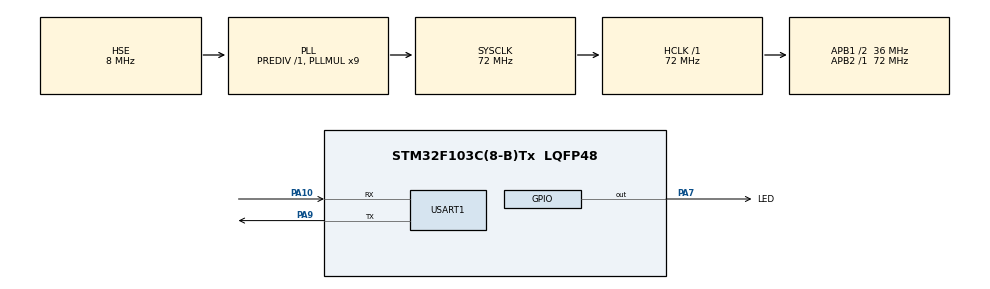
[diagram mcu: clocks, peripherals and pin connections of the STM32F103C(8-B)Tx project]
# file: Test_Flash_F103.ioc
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Mcu.Family=STM32F1
Mcu.Name=STM32F103C(8-B)Tx
Mcu.Package=LQFP48
NVIC.PriorityGroup=NVIC_PRIORITYGROUP_4
PA10.Mode=Asynchronous
PA10.Signal=USART1_RX
PA13.Mode=Serial_Wire
PA13.Signal=SYS_JTMS-SWDIO
PA14.Mode=Serial_Wire
PA14.Signal=SYS_JTCK-SWCLK
PA7.GPIO_Label=LED
PA7.Signal=GPIO_Output
PA9.Mode=Asynchronous
PA9.Signal=USART1_TX
PD0-OSC_IN.Mode=HSE-External-Oscillator
PD0-OSC_IN.Signal=RCC_OSC_IN
PD1-OSC_OUT.Mode=HSE-External-Oscillator
PD1-OSC_OUT.Signal=RCC_OSC_OUT
ProjectManager.HeapSize=0x200
ProjectManager.StackSize=0x400
ProjectManager.TargetToolchain=TrueSTUDIO
RCC.AHBFreq_Value=72000000
RCC.APB1CLKDivider=RCC_HCLK_DIV2
RCC.APB1Freq_Value=36000000
RCC.APB1TimFreq_Value=72000000
RCC.APB2Freq_Value=72000000
RCC.APB2TimFreq_Value=72000000
RCC.HCLKFreq_Value=72000000
RCC.PLLMUL=RCC_PLL_MUL9
RCC.PLLSourceVirtual=RCC_PLLSOURCE_HSE
RCC.SYSCLKFreq_VALUE=72000000
RCC.SYSCLKSource=RCC_SYSCLKSOURCE_PLLCLK
RCC.USBFreq_Value=72000000
USART1.VirtualMode=VM_ASYNC
board=custom

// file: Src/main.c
/* USER CODE BEGIN Header */
/**
  ******************************************************************************
  * @file           : main.c
  * @brief          : Main program body
  ******************************************************************************
  * @attention
  *
  * <h2><center>&copy; Copyright (c) 2019 STMicroelectronics.
  * All rights reserved.</center></h2>
  *
  * This software component is licensed by ST under BSD 3-Clause license,
  * the "License"; You may not use this file except in compliance with the
  * License. You may obtain a copy of the License at:
  *                        opensource.org/licenses/BSD-3-Clause
  *
  ******************************************************************************
  */
/* USER CODE END Header */

#include "main.h"

/* USER CODE BEGIN Includes */
#include "string.h"
#include "stdio.h"
#include "addr_pages.h"
/* USER CODE END Includes */

UART_HandleTypeDef huart1;

void SystemClock_Config(void);
static void MX_GPIO_Init(void);
static void MX_USART1_UART_Init(void);

/* USER CODE BEGIN 0 */
/*#define ENDMEMORY (0x0801FC00 + 1024) // последняя ячейка флеша (F103)

uint32_t flash_search_adress(uint32_t address, uint8_t cnt)
{
	uint8_t count_byte = cnt;

	while(count_byte)
	{
		if(0xFF == *(uint8_t*)address++) count_byte--;
		else count_byte = cnt;

		if(address == ENDMEMORY - 1) return 0;
	}

	return address -= cnt;
}*/
/* USER CODE END 0 */

int main(void)
{

  /* MCU Configuration--------------------------------------------------------*/

  /* Reset of all peripherals, Initializes the Flash interface and the Systick. */
  HAL_Init();

  /* Configure the system clock */
  SystemClock_Config();

  /* Initialize all configured peripherals */
  MX_GPIO_Init();
  MX_USART1_UART_Init();
  /* USER CODE BEGIN 2 */

  HAL_UART_Transmit(&huart1, (uint8_t*)"Start\n", 6, 100);
  //////////////////////////////////////////////////////////////////////////////////////////////////////////////////
  /////////////////////////////////////////// РАБОТА с ФЛЕШЕМ //////////////////////////////////////////////////////
  //////////////////////////////////////////////////////////////////////////////////////////////////////////////////

  #define MYADDR ADDR_FLASH_PAGE_127

  static FLASH_EraseInitTypeDef EraseInitStruct; // структура для очистки флеша

  EraseInitStruct.TypeErase = FLASH_TYPEERASE_PAGES; // постраничная очистка, FLASH_TYPEERASE_MASSERASE - очистка всего флеша
  EraseInitStruct.PageAddress = MYADDR; // адрес 127-ой страницы
  EraseInitStruct.NbPages = 1;                       // кол-во страниц для стирания
  //EraseInitStruct.Banks = FLASH_BANK_1; // FLASH_BANK_2 - банк №2, FLASH_BANK_BOTH - оба банка

  uint32_t page_error = 0; // переменная, в которую запишется адрес страницы при неудачном стирании

  char str[64] = {0,};

  ////////////////////////////// ОЧИСТКА ///////////////////////////////////
  HAL_FLASH_Unlock(); // разблокировать флеш

  if(HAL_FLASHEx_Erase(&EraseInitStruct, &page_error) != HAL_OK)
  {
	  uint32_t er = HAL_FLASH_GetError();
	  snprintf(str, 64, "ER %lu\n", er);
	  HAL_UART_Transmit(&huart1, (uint8_t*)str, strlen(str), 100);
	  while(1){}
  }

  HAL_UART_Transmit(&huart1, (uint8_t*)"Erase OK\n", 9, 100);

  HAL_FLASH_Lock(); // заблокировать флеш
  ///////////////////////// КОНЕЦ ОЧИСТКИ //////////////////////////////

  // 0x00U - No error
  // 0x01U - Programming error
  // 0x02U - Write protection error
  // 0x04U - Option validity error

  ////////////////////////////// ЗАПИСЬ числа 16 bits ///////////////////////////////////
  HAL_FLASH_Unlock(); // разблокировать флеш

  uint32_t address = MYADDR; // запись в начало страницы 127
  uint16_t idata[] = {0x1941, 0x1945};    // массив из двух чисел для записи

  for(uint8_t i = 0; i < 2; i++)
  {
	  if(HAL_FLASH_Program(FLASH_TYPEPROGRAM_HALFWORD, address, idata[i]) != HAL_OK)
	  {
		  uint32_t er = HAL_FLASH_GetError();
		  snprintf(str, 64, "ER %lu\n", er);
		  HAL_UART_Transmit(&huart1, (uint8_t*)str, strlen(str), 100);
		  while(1){}
	  }

	  address = address + 2;
  }

  HAL_UART_Transmit(&huart1, (uint8_t*)"Write 16 bits OK\n", strlen("Write 16 bits OK\n"), 100);

  HAL_FLASH_Lock(); // заблокировать флеш
  /////////////////////// КОНЕЦ ЗАПИСИ числа 16 bits ///////////////////////////

  ////////////////////////////// ЧТЕНИЕ числа 16 bits ///////////////////////////////////
  address = MYADDR;

  for(uint16_t i = 0; i < 2; i++)
  {
	  uint16_t dig16 = *(uint16_t*)address; // читаем число по адресу

	  snprintf(str, 64, "READ_%d Dec: %d Hex: 0x%04X\n", i, dig16, dig16);
	  HAL_UART_Transmit(&huart1, (uint8_t*)str, strlen(str), 100);

	  address = address + 2;
  }
  //////////////////////// КОНЕЦ ЧТЕНИЯ числа 16 bits ///////////////////////////////////

  ////////////////////////////// ЗАПИСЬ строки 8 bits ///////////////////////////////////
  HAL_FLASH_Unlock(); // разблокировать флеш

  address = MYADDR + 4; // смещаем адрес на 50 байт

  uint8_t data[] = " istarik.ru ";
  uint16_t data16 = 0, index0 = 0, index1 = 1;
  uint16_t len = strlen((char*)data);

  if(len % 2 != 0) // проверка кол-ва символов в массиве на чётность
  {
	  snprintf(str, 64, "ER uneven buff %d\n", len);
	  HAL_UART_Transmit(&huart1, (uint8_t*)str, strlen(str), 100);
	  while(1){}
  }

  for(uint16_t i = 0; i < len / 2; i++)
  {
	  data16 = ((uint16_t)data[index1] << 8) | data[index0];
	  index0 = index0 + 2;
	  index1 = index1 + 2;

	  if(HAL_FLASH_Program(FLASH_TYPEPROGRAM_HALFWORD, address, data16) != HAL_OK)
	  {
		  uint32_t er = HAL_FLASH_GetError();
		  snprintf(str, 64, "ER %lu\n", er);
		  HAL_UART_Transmit(&huart1, (uint8_t*)str, strlen(str), 100);
		  while(1){}
	  }

	  address = address + 2;
  }

  HAL_FLASH_Lock(); // заблокировать флеш

  HAL_UART_Transmit(&huart1, (uint8_t*)"Write 8 bits OK\n", strlen("Write 8 bits OK\n"), 100);
  /////////////////////// КОНЕЦ ЗАПИСИ строки 8 bits //////////////////////////

  ////////////////////////////// ЧТЕНИЕ строки 8 bits ///////////////////////////////////
  address = MYADDR + 4;

  char buf[64] = {0,};

  for(uint16_t i = 0; i < len; i++)
  {
	  buf[i] = *(uint32_t*)address++;
  }

  snprintf(str, 64, "Str: %s\n", buf);
  HAL_UART_Transmit(&huart1, (uint8_t*)str, strlen(str), 100);
  //////////////////////// КОНЕЦ ЧТЕНИЯ строки 8 bits ///////////////////////////////////

  //////////////////////// ПРОЧИТАТЬ ПОЛЬЗОВАТЕЛЬСКИЕ БИТЫ - User Data  /////////////////////////////
  uint32_t user_bit = HAL_FLASHEx_OBGetUserData(OB_DATA_ADDRESS_DATA0);
  snprintf(str, 64, "User_bit_0: %lu\n", user_bit);
  HAL_UART_Transmit(&huart1, (uint8_t*)str, strlen(str), 100);

  user_bit = HAL_FLASHEx_OBGetUserData(OB_DATA_ADDRESS_DATA1);
  snprintf(str, 64, "User_bit_1: %lu\n", user_bit);
  HAL_UART_Transmit(&huart1, (uint8_t*)str, strlen(str), 100);
  //////////////////////// КОНЕЦ ЧТЕНИЯ /////////////////////////////

  //uint32_t adr = flash_search_adress(0x0801FC00, 10);

  //snprintf(str, 64, "Adr. Dec: %lu Hex: %lx \n", adr, adr);
  //HAL_UART_Transmit(&huart1, (uint8_t*)str, strlen(str), 100);

  /* USER CODE END 2 */

  /* Infinite loop */
  while (1)
  {

  }
}

void SystemClock_Config(void)
{
  RCC_OscInitTypeDef RCC_OscInitStruct = {0};
  RCC_ClkInitTypeDef RCC_ClkInitStruct = {0};

  /** Initializes the CPU, AHB and APB busses clocks
  */
  RCC_OscInitStruct.OscillatorType = RCC_OSCILLATORTYPE_HSE;
  RCC_OscInitStruct.HSEState = RCC_HSE_ON;
  RCC_OscInitStruct.HSEPredivValue = RCC_HSE_PREDIV_DIV1;
  RCC_OscInitStruct.HSIState = RCC_HSI_ON;
  RCC_OscInitStruct.PLL.PLLState = RCC_PLL_ON;
  RCC_OscInitStruct.PLL.PLLSource = RCC_PLLSOURCE_HSE;
  RCC_OscInitStruct.PLL.PLLMUL = RCC_PLL_MUL9;
  if (HAL_RCC_OscConfig(&RCC_OscInitStruct) != HAL_OK)
  {
    Error_Handler();
  }
  /** Initializes the CPU, AHB and APB busses clocks
  */
  RCC_ClkInitStruct.ClockType = RCC_CLOCKTYPE_HCLK|RCC_CLOCKTYPE_SYSCLK
                              |RCC_CLOCKTYPE_PCLK1|RCC_CLOCKTYPE_PCLK2;
  RCC_ClkInitStruct.SYSCLKSource = RCC_SYSCLKSOURCE_PLLCLK;
  RCC_ClkInitStruct.AHBCLKDivider = RCC_SYSCLK_DIV1;
  RCC_ClkInitStruct.APB1CLKDivider = RCC_HCLK_DIV2;
  RCC_ClkInitStruct.APB2CLKDivider = RCC_HCLK_DIV1;

  if (HAL_RCC_ClockConfig(&RCC_ClkInitStruct, FLASH_LATENCY_2) != HAL_OK)
  {
    Error_Handler();
  }
}

static void MX_USART1_UART_Init(void)
{

  huart1.Instance = USART1;
  huart1.Init.BaudRate = 56000;
  huart1.Init.WordLength = UART_WORDLENGTH_8B;
  huart1.Init.StopBits = UART_STOPBITS_1;
  huart1.Init.Parity = UART_PARITY_NONE;
  huart1.Init.Mode = UART_MODE_TX_RX;
  huart1.Init.HwFlowCtl = UART_HWCONTROL_NONE;
  huart1.Init.OverSampling = UART_OVERSAMPLING_16;
  if (HAL_UART_Init(&huart1) != HAL_OK)
  {
    Error_Handler();
  }

}

static void MX_GPIO_Init(void)
{
  GPIO_InitTypeDef GPIO_InitStruct = {0};

  /* GPIO Ports Clock Enable */
  __HAL_RCC_GPIOD_CLK_ENABLE();
  __HAL_RCC_GPIOA_CLK_ENABLE();

  /*Configure GPIO pin Output Level */
  HAL_GPIO_WritePin(LED_GPIO_Port, LED_Pin, GPIO_PIN_RESET);

  /*Configure GPIO pin : LED_Pin */
  GPIO_InitStruct.Pin = LED_Pin;
  GPIO_InitStruct.Mode = GPIO_MODE_OUTPUT_PP;
  GPIO_InitStruct.Pull = GPIO_NOPULL;
  GPIO_InitStruct.Speed = GPIO_SPEED_FREQ_LOW;
  HAL_GPIO_Init(LED_GPIO_Port, &GPIO_InitStruct);

}

void Error_Handler(void)
{
}

/************************ (C) COPYRIGHT STMicroelectronics *****END OF FILE****/
